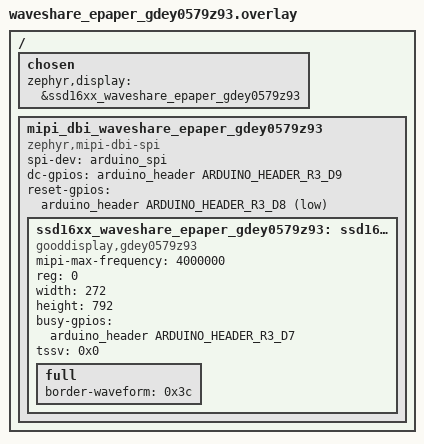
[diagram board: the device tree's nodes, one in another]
/*
 * Copyright (c) 2026, Dominic Hanssen
 *
 * SPDX-License-Identifier: Apache-2.0
 */

#include "dts/waveshare_epaper_common.dtsi"

/ {
	chosen {
		zephyr,display = &ssd16xx_waveshare_epaper_gdey0579z93;
	};

	mipi_dbi_waveshare_epaper_gdey0579z93 {
		compatible = "zephyr,mipi-dbi-spi";
		spi-dev = <&arduino_spi>;
		dc-gpios = <&arduino_header ARDUINO_HEADER_R3_D9 GPIO_ACTIVE_HIGH>;
		reset-gpios = <&arduino_header ARDUINO_HEADER_R3_D8 GPIO_ACTIVE_LOW>;
		#address-cells = <1>;
		#size-cells = <0>;

		ssd16xx_waveshare_epaper_gdey0579z93: ssd16xxfb@0 {
			compatible = "gooddisplay,gdey0579z93", "solomon,ssd1683";
			mipi-max-frequency = <4000000>;
			reg = <0>;
			width = <272>;
			height = <792>;
			busy-gpios = <&arduino_header ARDUINO_HEADER_R3_D7 GPIO_ACTIVE_HIGH>;

			tssv = <0x0>;

			full {
				border-waveform = <0x3c>;
			};
		};
	};
};
